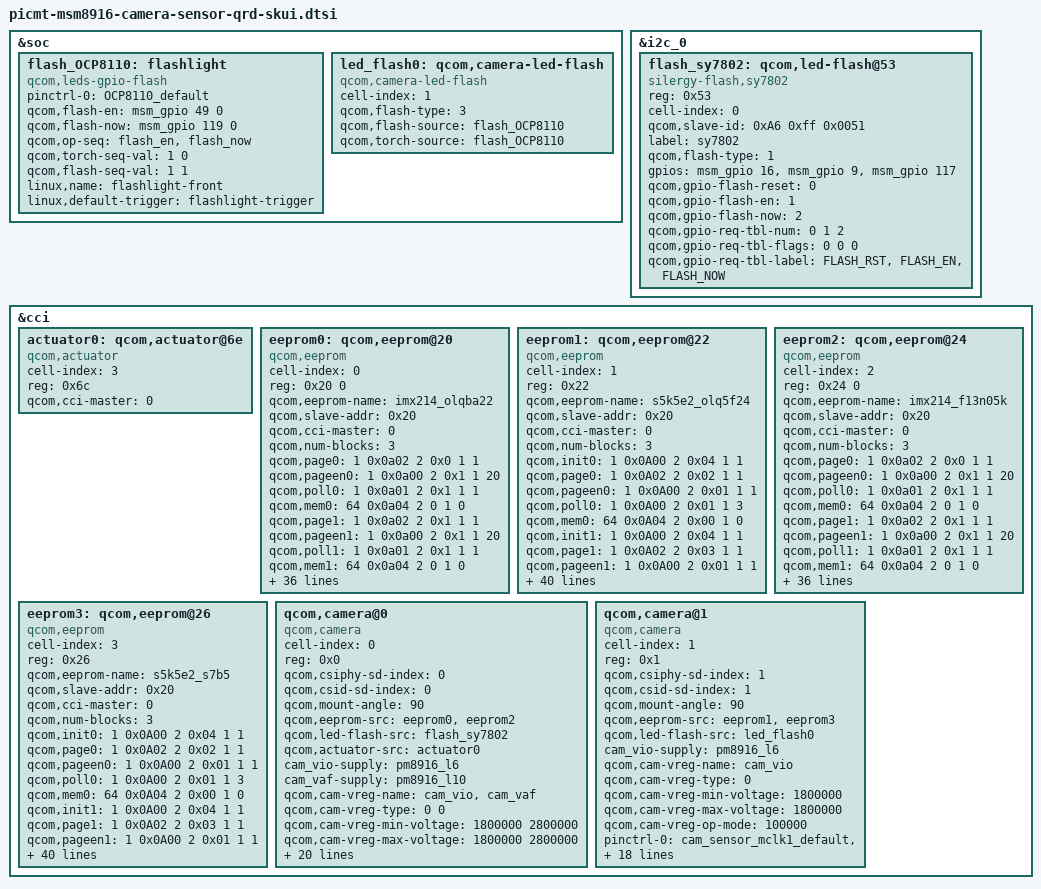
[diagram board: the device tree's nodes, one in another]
/*
 * Copyright (c) 2014, The Linux Foundation. All rights reserved.
 *
 * This program is free software; you can redistribute it and/or modify
 * it under the terms of the GNU General Public License version 2 and
 * only version 2 as published by the Free Software Foundation.
 *
 * This program is distributed in the hope that it will be useful,
 * but WITHOUT ANY WARRANTY; without even the implied warranty of
 * MERCHANTABILITY or FITNESS FOR A PARTICULAR PURPOSE.  See the
 * GNU General Public License for more details.
 */

&soc {
	flash_OCP8110:flashlight {
		compatible = "qcom,leds-gpio-flash";
		status = "okay";
		pinctrl-names = "flash_default";
		pinctrl-0 = <&OCP8110_default>;
		qcom,flash-en = <&msm_gpio 49 0>;
		qcom,flash-now = <&msm_gpio 119 0>;
		qcom,op-seq = "flash_en", "flash_now";
		qcom,torch-seq-val = <1 0>;
		qcom,flash-seq-val = <1 1>;
		linux,name = "flashlight-front";
		linux,default-trigger = "flashlight-trigger";
	};

	/delete-node/ qcom,camera-led-flash;
	led_flash0: qcom,camera-led-flash {
		cell-index = <1>;
		compatible = "qcom,camera-led-flash";
		qcom,flash-type = <3>;
		qcom,flash-source = <&flash_OCP8110>;
		qcom,torch-source = <&flash_OCP8110>;
	};
};

&i2c_0 { /* BLSP1 QUP2 */
	flash_sy7802:qcom,led-flash@53 {
		reg = <0x53>;
		cell-index = <0>;
		qcom,slave-id = <0xA6 0xff 0x0051>;
		compatible = "silergy-flash,sy7802";
		label = "sy7802";
		qcom,flash-type = <1>;
		gpios = <&msm_gpio 16 0>,
				<&msm_gpio 9 0>,
				<&msm_gpio 117 0>;
		qcom,gpio-flash-reset = <0>;
		qcom,gpio-flash-en = <1>;
		qcom,gpio-flash-now = <2>;
		qcom,gpio-req-tbl-num = <0 1 2>;
		qcom,gpio-req-tbl-flags = <0 0 0>;
		qcom,gpio-req-tbl-label = "FLASH_RST",
				"FLASH_EN",
				"FLASH_NOW";
	};
};

&cci {
	/delete-node/ qcom,actuator@0;
	actuator0: qcom,actuator@6e {
		cell-index = <3>;
		reg = <0x6c>;
		compatible = "qcom,actuator";
		qcom,cci-master = <0>;
	};

	/delete-node/ qcom,eeprom@6b;
	/delete-node/ qcom,eeprom@1;
	eeprom0: qcom,eeprom@20 {
		cell-index = <0>;
		reg = <0x20 0>;
		qcom,eeprom-name = "imx214_olqba22";
		compatible = "qcom,eeprom";
		qcom,slave-addr = <0x20>;
		qcom,cci-master = <0>;
		qcom,num-blocks = <3>;

		qcom,page0 = <1 0x0a02 2 0x0 1 1>;
		qcom,pageen0 = <1 0x0a00 2 0x1 1 20>;
		qcom,poll0 = <1 0x0a01 2 0x1 1 1>;
		qcom,mem0 = <64 0x0a04 2 0 1 0>;

		qcom,page1 = <1 0x0a02 2 0x1 1 1>;
		qcom,pageen1 = <1 0x0a00 2 0x1 1 20>;
		qcom,poll1 = <1 0x0a01 2 0x1 1 1>;
		qcom,mem1 = <64 0x0a04 2 0 1 0>;

		qcom,page2 = <1 0x0a02 2 0x2 1 1>;
		qcom,pageen2 = <1 0x0a00 2 0x1 1 20>;
		qcom,poll2 = <1 0x0a01 2 0x1 1 1>;
		qcom,mem2 = <64 0x0a04 2 0 1 0>;

		cam_vio-supply = <&pm8916_l6>;
		qcom,cam-vreg-name = "cam_vio";
		qcom,cam-vreg-type = <0>;
		qcom,cam-vreg-min-voltage = <1800000>;
		qcom,cam-vreg-max-voltage = <1800000>;
		qcom,cam-vreg-op-mode = <100000>;
		pinctrl-names = "cam_default", "cam_suspend";
		pinctrl-0 = <&cam_sensor_mclk0_default &cam_sensor_rear_default>;
		pinctrl-1 = <&cam_sensor_mclk0_sleep &cam_sensor_rear_sleep>;
		gpios = <&msm_gpio 26 0>,
			<&msm_gpio 35 0>,
			<&msm_gpio 31 0>,
			<&msm_gpio 34 0>;
		qcom,gpio-reset = <1>;
		qcom,gpio-vdig = <2>;
		qcom,gpio-vana = <3>;
		qcom,gpio-req-tbl-num = <0 1 2 3>;
		qcom,gpio-req-tbl-flags = <1 0 0 0>;
		qcom,gpio-req-tbl-label = "CAMIF_MCLK",
			"CAM_RESET1",
			"CAM_VDIG",
			"CAM_VANA";
		qcom,cam-power-seq-type = "sensor_gpio",
			"sensor_gpio",
			"sensor_gpio",
			"sensor_gpio",
			"sensor_gpio",
			"sensor_gpio",
			"sensor_clk",
			"sensor_i2c_mux";
		qcom,cam-power-seq-val = "sensor_gpio_reset",
			"sensor_gpio_vana",
			"sensor_gpio_vdig",
			"sensor_gpio_vana",
			"sensor_gpio_vdig",
			"sensor_gpio_reset",
			"sensor_cam_mclk",
			"none";
		qcom,cam-power-seq-cfg-val = <0 0 0 1 1 1 1 24000000 0>;
		qcom,cam-power-seq-delay = <1 1 1 1 30 30 10 1>;
		clocks = <&clock_gcc clk_mclk0_clk_src>,
				<&clock_gcc clk_gcc_camss_mclk0_clk>;
		clock-names = "cam_src_clk", "cam_clk";
	};

	eeprom1: qcom,eeprom@22 {
		cell-index = <1>;
		reg = <0x22>;
		qcom,eeprom-name = "s5k5e2_olq5f24";
		compatible = "qcom,eeprom";
		qcom,slave-addr = <0x20>;
		qcom,cci-master = <0>;
		qcom,num-blocks = <3>;

		qcom,init0 =   <1 0x0A00 2 0x04 1 1>;
		qcom,page0 =   <1 0x0A02 2 0x02 1 1>;
		qcom,pageen0 = <1 0x0A00 2 0x01 1 1>;
		qcom,poll0 =   <1 0x0A00 2 0x01 1 3>;
		qcom,mem0 =   <64 0x0A04 2 0x00 1 0>;

		qcom,init1 =   <1 0x0A00 2 0x04 1 1>;
		qcom,page1 =   <1 0x0A02 2 0x03 1 1>;
		qcom,pageen1 = <1 0x0A00 2 0x01 1 1>;
		qcom,poll1 =   <1 0x0A00 2 0x01 1 3>;
		qcom,mem1 =   <64 0x0A04 2 0x00 1 0>;

		qcom,init2 =   <1 0x0A00 2 0x04 1 1>;
		qcom,page2 =   <1 0x0A02 2 0x0F 1 1>;
		qcom,pageen2 = <1 0x0A00 2 0x01 1 1>;
		qcom,poll2 =   <1 0x0A00 2 0x01 1 3>;
		qcom,mem2 =   <64 0x0A04 2 0x00 1 0>;

		cam_vio-supply = <&pm8916_l6>;
		qcom,cam-vreg-name = "cam_vio";
		qcom,cam-vreg-type = <0>;
		qcom,cam-vreg-min-voltage = <1800000>;
		qcom,cam-vreg-max-voltage = <1800000>;
		qcom,cam-vreg-op-mode = <100000>;
		pinctrl-names = "cam_default", "cam_suspend";
		pinctrl-0 = <&cam_sensor_mclk1_default &cam_sensor_front_default>;
		pinctrl-1 = <&cam_sensor_mclk1_sleep &cam_sensor_front_sleep>;
		gpios = <&msm_gpio 27 0>,
			<&msm_gpio 33 0>,
			<&msm_gpio 32 0>,
			<&msm_gpio 34 0>;
		qcom,gpio-standby = <1>;
		qcom,gpio-vdig = <2>;
		qcom,gpio-vana = <3>;
		qcom,gpio-req-tbl-num = <0 1 2 3>;
		qcom,gpio-req-tbl-flags = <1 0 0 0>;
		qcom,gpio-req-tbl-label = "CAMIF_MCLK",
			"CAM_STANDBY",
			"CAM_VDIG",
			"CAM_VANA";
		qcom,cam-power-seq-type = "sensor_gpio",
			"sensor_gpio",
			"sensor_gpio",
			"sensor_gpio",
			"sensor_gpio",
			"sensor_gpio",
			"sensor_clk",
			"sensor_i2c_mux";
		qcom,cam-power-seq-val = 	"sensor_gpio_standby",
			"sensor_gpio_vana",
			"sensor_gpio_vdig",
			"sensor_gpio_vana",
			"sensor_gpio_vdig",
			"sensor_gpio_standby",
			"sensor_cam_mclk",
			"none";

		qcom,cam-power-seq-cfg-val = <0 0 0 1 1 1 1 23880000 0>;
		qcom,cam-power-seq-delay = <1 1 1 1 30 30 10 1>;
		qcom,mclk-23880000;
		clocks = <&clock_gcc clk_mclk1_clk_src>,
				<&clock_gcc clk_gcc_camss_mclk1_clk>;
		clock-names = "cam_src_clk", "cam_clk";
	};

	eeprom2: qcom,eeprom@24 {
		cell-index = <2>;
		reg = <0x24 0>;
		qcom,eeprom-name = "imx214_f13n05k";
		compatible = "qcom,eeprom";
		qcom,slave-addr = <0x20>;
		qcom,cci-master = <0>;
		qcom,num-blocks = <3>;

		qcom,page0 = <1 0x0a02 2 0x0 1 1>;
		qcom,pageen0 = <1 0x0a00 2 0x1 1 20>;
		qcom,poll0 = <1 0x0a01 2 0x1 1 1>;
		qcom,mem0 = <64 0x0a04 2 0 1 0>;

		qcom,page1 = <1 0x0a02 2 0x1 1 1>;
		qcom,pageen1 = <1 0x0a00 2 0x1 1 20>;
		qcom,poll1 = <1 0x0a01 2 0x1 1 1>;
		qcom,mem1 = <64 0x0a04 2 0 1 0>;

		qcom,page2 = <1 0x0a02 2 0x2 1 1>;
		qcom,pageen2 = <1 0x0a00 2 0x1 1 20>;
		qcom,poll2 = <1 0x0a01 2 0x1 1 1>;
		qcom,mem2 = <64 0x0a04 2 0 1 0>;

		cam_vio-supply = <&pm8916_l6>;
		qcom,cam-vreg-name = "cam_vio";
		qcom,cam-vreg-type = <0>;
		qcom,cam-vreg-min-voltage = <1800000>;
		qcom,cam-vreg-max-voltage = <1800000>;
		qcom,cam-vreg-op-mode = <100000>;
		pinctrl-names = "cam_default", "cam_suspend";
		pinctrl-0 = <&cam_sensor_mclk0_default &cam_sensor_rear_default>;
		pinctrl-1 = <&cam_sensor_mclk0_sleep &cam_sensor_rear_sleep>;
		gpios = <&msm_gpio 26 0>,
			<&msm_gpio 35 0>,
			<&msm_gpio 31 0>,
			<&msm_gpio 34 0>;
		qcom,gpio-reset = <1>;
		qcom,gpio-vdig = <2>;
		qcom,gpio-vana = <3>;
		qcom,gpio-req-tbl-num = <0 1 2 3>;
		qcom,gpio-req-tbl-flags = <1 0 0 0>;
		qcom,gpio-req-tbl-label = "CAMIF_MCLK",
			"CAM_RESET1",
			"CAM_VDIG",
			"CAM_VANA";
		qcom,cam-power-seq-type = "sensor_gpio",
			"sensor_gpio",
			"sensor_gpio",
			"sensor_gpio",
			"sensor_gpio",
			"sensor_gpio",
			"sensor_clk",
			"sensor_i2c_mux";
		qcom,cam-power-seq-val = "sensor_gpio_reset",
			"sensor_gpio_vana",
			"sensor_gpio_vdig",
			"sensor_gpio_vana",
			"sensor_gpio_vdig",
			"sensor_gpio_reset",
			"sensor_cam_mclk",
			"none";
		qcom,cam-power-seq-cfg-val = <0 0 0 1 1 1 1 24000000 0>;
		qcom,cam-power-seq-delay = <1 1 1 1 30 30 10 1>;
		clocks = <&clock_gcc clk_mclk0_clk_src>,
				<&clock_gcc clk_gcc_camss_mclk0_clk>;
		clock-names = "cam_src_clk", "cam_clk";
	};

	eeprom3: qcom,eeprom@26 {
		cell-index = <3>;
		reg = <0x26>;
		qcom,eeprom-name = "s5k5e2_s7b5";
		compatible = "qcom,eeprom";
		qcom,slave-addr = <0x20>;
		qcom,cci-master = <0>;
		qcom,num-blocks = <3>;

		qcom,init0 =   <1 0x0A00 2 0x04 1 1>;
		qcom,page0 =   <1 0x0A02 2 0x02 1 1>;
		qcom,pageen0 = <1 0x0A00 2 0x01 1 1>;
		qcom,poll0 =   <1 0x0A00 2 0x01 1 3>;
		qcom,mem0 =   <64 0x0A04 2 0x00 1 0>;

		qcom,init1 =   <1 0x0A00 2 0x04 1 1>;
		qcom,page1 =   <1 0x0A02 2 0x03 1 1>;
		qcom,pageen1 = <1 0x0A00 2 0x01 1 1>;
		qcom,poll1 =   <1 0x0A00 2 0x01 1 3>;
		qcom,mem1 =   <64 0x0A04 2 0x00 1 0>;

		qcom,init2 =   <1 0x0A00 2 0x04 1 1>;
		qcom,page2 =   <1 0x0A02 2 0x0F 1 1>;
		qcom,pageen2 = <1 0x0A00 2 0x01 1 1>;
		qcom,poll2 =   <1 0x0A00 2 0x01 1 3>;
		qcom,mem2 =   <64 0x0A04 2 0x00 1 0>;

		cam_vio-supply = <&pm8916_l6>;
		qcom,cam-vreg-name = "cam_vio";
		qcom,cam-vreg-type = <0>;
		qcom,cam-vreg-min-voltage = <1800000>;
		qcom,cam-vreg-max-voltage = <1800000>;
		qcom,cam-vreg-op-mode = <100000>;
		pinctrl-names = "cam_default", "cam_suspend";
		pinctrl-0 = <&cam_sensor_mclk1_default &cam_sensor_front_default>;
		pinctrl-1 = <&cam_sensor_mclk1_sleep &cam_sensor_front_sleep>;
		gpios = <&msm_gpio 27 0>,
			<&msm_gpio 33 0>,
			<&msm_gpio 32 0>,
			<&msm_gpio 34 0>;
		qcom,gpio-standby = <1>;
		qcom,gpio-vdig = <2>;
		qcom,gpio-vana = <3>;
		qcom,gpio-req-tbl-num = <0 1 2 3>;
		qcom,gpio-req-tbl-flags = <1 0 0 0>;
		qcom,gpio-req-tbl-label = "CAMIF_MCLK",
			"CAM_STANDBY",
			"CAM_VDIG",
			"CAM_VANA";
		qcom,cam-power-seq-type = "sensor_gpio",
			"sensor_gpio",
			"sensor_gpio",
			"sensor_gpio",
			"sensor_gpio",
			"sensor_gpio",
			"sensor_clk",
			"sensor_i2c_mux";
		qcom,cam-power-seq-val = 	"sensor_gpio_standby",
			"sensor_gpio_vana",
			"sensor_gpio_vdig",
			"sensor_gpio_vana",
			"sensor_gpio_vdig",
			"sensor_gpio_standby",
			"sensor_cam_mclk",
			"none";

		qcom,cam-power-seq-cfg-val = <0 0 0 1 1 1 1 23880000 0>;
		qcom,cam-power-seq-delay = <1 1 1 1 30 30 10 1>;
		qcom,mclk-23880000;
		clocks = <&clock_gcc clk_mclk1_clk_src>,
				<&clock_gcc clk_gcc_camss_mclk1_clk>;
		clock-names = "cam_src_clk", "cam_clk";
	};

	qcom,camera@0 {
		cell-index = <0>;
		compatible = "qcom,camera";
		reg = <0x0>;
		qcom,csiphy-sd-index = <0>;
		qcom,csid-sd-index = <0>;
		qcom,mount-angle = <90>;
		qcom,eeprom-src = <&eeprom0 &eeprom2>;
		qcom,led-flash-src = <&flash_sy7802>;
		qcom,actuator-src = <&actuator0>;
		cam_vio-supply = <&pm8916_l6>;
		cam_vaf-supply = <&pm8916_l10>;
		qcom,cam-vreg-name = "cam_vio","cam_vaf";
		qcom,cam-vreg-type = <0 0>;
		qcom,cam-vreg-min-voltage = <1800000 2800000>;
		qcom,cam-vreg-max-voltage = <1800000 2800000>;
		qcom,cam-vreg-op-mode = <100000 100000>;
		pinctrl-names = "cam_default", "cam_suspend";
		pinctrl-0 = <&cam_sensor_mclk0_default &cam_sensor_rear_default>;
		pinctrl-1 = <&cam_sensor_mclk0_sleep &cam_sensor_rear_sleep>;
		gpios = <&msm_gpio 26 0>,
			<&msm_gpio 35 0>,
			<&msm_gpio 31 0>,
			<&msm_gpio 34 0>;
		qcom,gpio-reset = <1>;
		qcom,gpio-vdig = <2>;
		qcom,gpio-vana = <3>;
		qcom,gpio-req-tbl-num = <0 1 2 3>;
		qcom,gpio-req-tbl-flags = <1 0 0 0>;
		qcom,gpio-req-tbl-label = "CAMIF_MCLK",
			"CAM_RESET1",
			"CAM_VDIG",
			"CAM_VANA";
		qcom,sensor-position = <0>;
		qcom,sensor-mode = <0>;
		qcom,cci-master = <0>;
		qcom,mclk-23880000;
		status = "ok";
		clocks = <&clock_gcc clk_mclk0_clk_src>,
				<&clock_gcc clk_gcc_camss_mclk0_clk>;
		clock-names = "cam_src_clk", "cam_clk";
	};

	qcom,camera@1 {
		cell-index = <1>;
		compatible = "qcom,camera";
		reg = <0x1>;
		qcom,csiphy-sd-index = <1>;
		qcom,csid-sd-index = <1>;
		qcom,mount-angle = <90>;
		qcom,eeprom-src = <&eeprom1 &eeprom3>;
		qcom,led-flash-src = <&led_flash0>;
		cam_vio-supply = <&pm8916_l6>;
		qcom,cam-vreg-name = "cam_vio";
		qcom,cam-vreg-type = <0>;
		qcom,cam-vreg-min-voltage = <1800000>;
		qcom,cam-vreg-max-voltage = <1800000>;
		qcom,cam-vreg-op-mode = <100000>;
		pinctrl-names = "cam_default", "cam_suspend";
		pinctrl-0 = <&cam_sensor_mclk1_default &cam_sensor_front_default>;
		pinctrl-1 = <&cam_sensor_mclk1_sleep &cam_sensor_front_sleep>;
		gpios = <&msm_gpio 27 0>,
			<&msm_gpio 33 0>,
			<&msm_gpio 32 0>,
			<&msm_gpio 34 0>;
		qcom,gpio-standby = <1>;
		qcom,gpio-vdig = <2>;
		qcom,gpio-vana = <3>;
		qcom,gpio-req-tbl-num = <0 1 2 3>;
		qcom,gpio-req-tbl-flags = <1 0 0 0>;
		qcom,gpio-req-tbl-label = "CAMIF_MCLK",
			"CAM_STANDBY",
			"CAM_VDIG",
			"CAM_VANA";
		qcom,sensor-position = <1>;
		qcom,sensor-mode = <0>;
		qcom,cci-master = <0>;
		qcom,mclk-23880000;
		status = "ok";
		clocks = <&clock_gcc clk_mclk1_clk_src>,
				<&clock_gcc clk_gcc_camss_mclk1_clk>;
		clock-names = "cam_src_clk", "cam_clk";
	};
};

